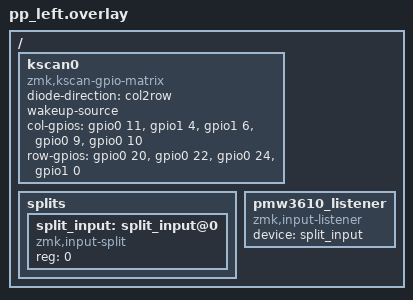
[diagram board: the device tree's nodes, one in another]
#include "pp_left-layout.dtsi"

/ {
    kscan0: kscan0 {
        compatible = "zmk,kscan-gpio-matrix";
        diode-direction = "col2row";
        wakeup-source;

        col-gpios
            = <&gpio0 11 GPIO_ACTIVE_HIGH>
            , <&gpio1 4 GPIO_ACTIVE_HIGH>
            , <&gpio1 6 GPIO_ACTIVE_HIGH>
            , <&gpio0 9 GPIO_ACTIVE_HIGH>
            , <&gpio0 10 GPIO_ACTIVE_HIGH>
            ;

        row-gpios
            = <&gpio0 20 (GPIO_ACTIVE_HIGH | GPIO_PULL_DOWN)>
            , <&gpio0 22 (GPIO_ACTIVE_HIGH | GPIO_PULL_DOWN)>
            , <&gpio0 24 (GPIO_ACTIVE_HIGH | GPIO_PULL_DOWN)>
            , <&gpio1 0 (GPIO_ACTIVE_HIGH | GPIO_PULL_DOWN)>
            ;
    };

    splits {
        #address-cells = <1>;
        #size-cells = <0>;

        split_input: split_input@0 {
            compatible = "zmk,input-split";
            reg = <0>;
        };
    };

    pmw3610_listener {
        compatible = "zmk,input-listener";
        device = <&split_input>;
    };
};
